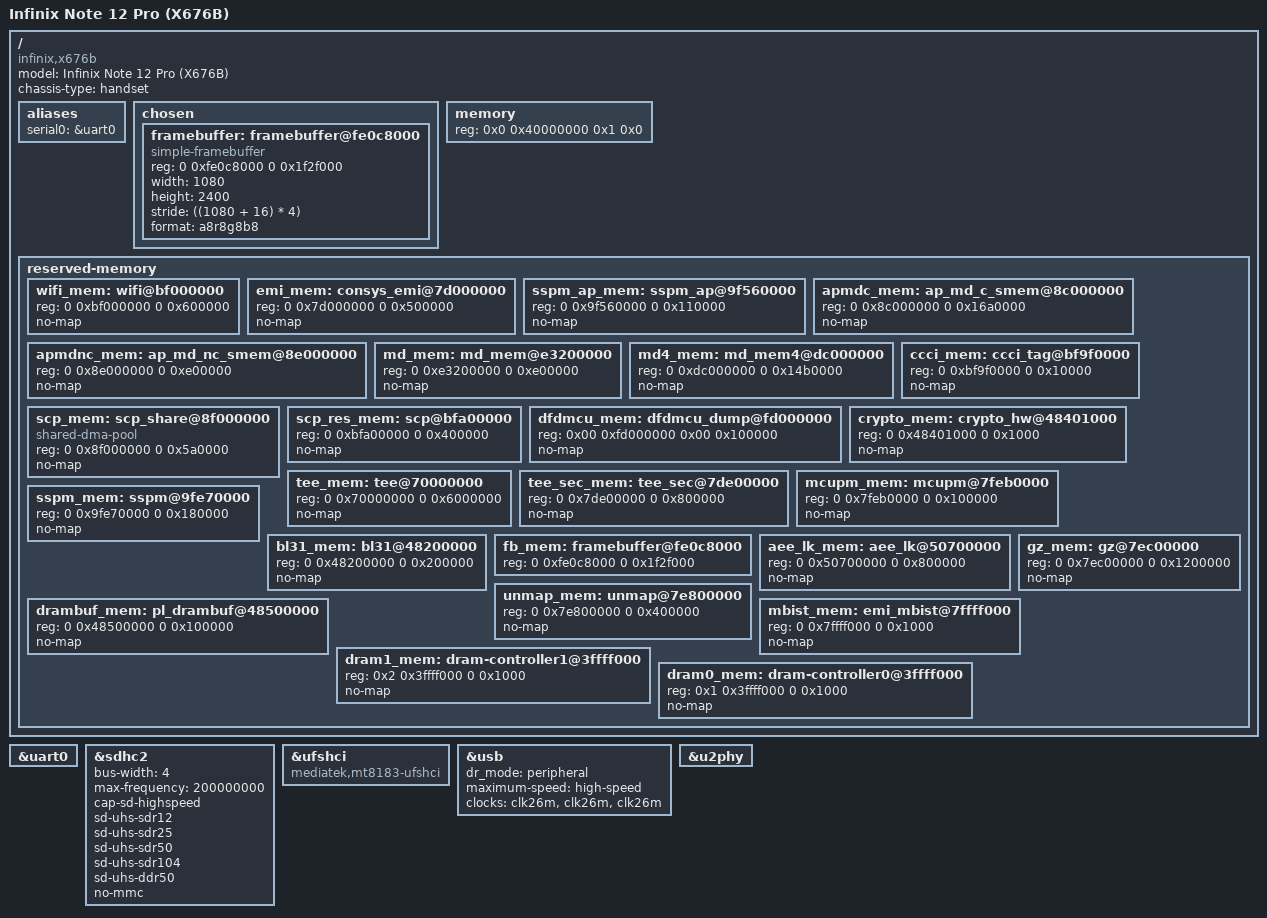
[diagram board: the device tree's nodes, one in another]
/*
 * SPDX-License-Identifier: (GPL-2.0 OR MIT)
 */

/dts-v1/;
#include "mt6789.dtsi"
#include <dt-bindings/gpio/gpio.h>
#include <dt-bindings/input/input.h>

/ {
	model = "Infinix Note 12 Pro (X676B)";
	chassis-type = "handset";
	compatible = "infinix,x676b", "mediatek,mt6789";

	#address-cells = <2>;
	#size-cells = <2>;

	aliases {
		serial0 = &uart0;
	};

	chosen {
		#address-cells = <2>;
		#size-cells = <2>;
		ranges;

		framebuffer: framebuffer@fe0c8000 {
			compatible = "simple-framebuffer";
			reg = <0 0xfe0c8000 0 0x1f2f000>;
			width = <1080>;
			height = <2400>;
			stride = <((1080 + 16) * 4)>;
			format = "a8r8g8b8";
		};
	};

	memory {
		device_type = "memory";
		reg = <0x0 0x40000000 0x1 0x0>;
	};

	reserved-memory {
		#address-cells = <2>;
		#size-cells = <2>;

		wifi_mem: wifi@bf000000 {
			reg = <0 0xbf000000 0 0x600000>;
			no-map;
		};

		emi_mem: consys_emi@7d000000 {
			reg = <0 0x7d000000 0 0x500000>;
			no-map;
		};

		sspm_ap_mem: sspm_ap@9f560000 {
			reg = <0 0x9f560000 0 0x110000>;
			no-map;
		};

		apmdc_mem: ap_md_c_smem@8c000000 {
			reg = <0 0x8c000000 0 0x16a0000>;
			no-map;
		};

		apmdnc_mem: ap_md_nc_smem@8e000000 {
			reg = <0 0x8e000000 0 0xe00000>;
			no-map;
		};

		md_mem: md_mem@e3200000 {
			reg = <0 0xe3200000 0 0xe00000>;
			no-map;
		};

		md4_mem: md_mem4@dc000000 {
			reg = <0 0xdc000000 0 0x14b0000>;
			no-map;
		};

		ccci_mem: ccci_tag@bf9f0000 {
			reg = <0 0xbf9f0000 0 0x10000>;
			no-map;
		};

		scp_mem: scp_share@8f000000 {
			reg = <0 0x8f000000 0 0x5a0000>;
			compatible = "shared-dma-pool";
			no-map;
		};

		scp_res_mem: scp@bfa00000 {
			reg = <0 0xbfa00000 0 0x400000>;
			no-map;
		};

		dfdmcu_mem: dfdmcu_dump@fd000000 {
			reg = <0x00 0xfd000000 0x00 0x100000>;
			no-map;
		};

		crypto_mem: crypto_hw@48401000 {
			reg = <0 0x48401000 0 0x1000>;
			no-map;
		};

		tee_mem: tee@70000000 {
			reg = <0 0x70000000 0 0x6000000>;
			no-map;
		};

		tee_sec_mem: tee_sec@7de00000 {
			reg = <0 0x7de00000 0 0x800000>;
			no-map;
		};

		mcupm_mem: mcupm@7feb0000 {
			reg = <0 0x7feb0000 0 0x100000>;
			no-map;
		};

		sspm_mem: sspm@9fe70000 {
			reg = <0 0x9fe70000 0 0x180000>;
			no-map;
		};

		bl31_mem: bl31@48200000 {
			reg = <0 0x48200000 0 0x200000>;
			no-map;
		};

		fb_mem: framebuffer@fe0c8000 {
			reg = <0 0xfe0c8000 0 0x1f2f000>;
			/* no-map removed so U-Boot can access framebuffer */
		};

		aee_lk_mem: aee_lk@50700000 {
			reg = <0 0x50700000 0 0x800000>;
			no-map;
		};

		drambuf_mem: pl_drambuf@48500000 {
			reg = <0 0x48500000 0 0x100000>;
			no-map;
		};

		unmap_mem: unmap@7e800000 {
			reg = <0 0x7e800000 0 0x400000>;
			no-map;
		};

		gz_mem: gz@7ec00000 {
			reg = <0 0x7ec00000 0 0x1200000>;
			no-map;
		};

		mbist_mem: emi_mbist@7ffff000 {
			reg = <0 0x7ffff000 0 0x1000>;
			no-map;
		};

		dram1_mem: dram-controller1@3ffff000 {
			reg = <0x2 0x3ffff000 0 0x1000>;
			no-map;
		};

		dram0_mem: dram-controller0@3ffff000 {
			reg = <0x1 0x3ffff000 0 0x1000>;
			no-map;
		};
	};
};

&uart0 {
	status = "okay";
};

&sdhc2 {
	status = "okay";
	bus-width = <4>;
	max-frequency = <200000000>;
	cap-sd-highspeed;
	sd-uhs-sdr12;
	sd-uhs-sdr25;
	sd-uhs-sdr50;
	sd-uhs-sdr104;
	sd-uhs-ddr50;
	no-mmc;
};

&ufshci {
	compatible = "mediatek,mt8183-ufshci";
	status = "okay";
};

&usb {
	status = "okay";

	dr_mode = "peripheral";
	maximum-speed = "high-speed";

	/* Fix clock names to match MUSB driver expectations */
	clocks = <&clk26m>, <&clk26m>, <&clk26m>;
	clock-names = "usbpll", "usbmcu", "usb";
};

&u2phy {
	status = "okay";
};
